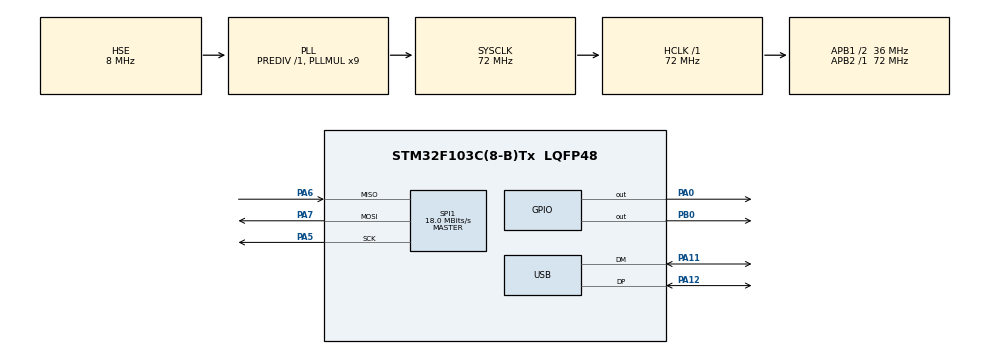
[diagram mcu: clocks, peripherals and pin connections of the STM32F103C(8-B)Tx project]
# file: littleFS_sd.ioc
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Mcu.Family=STM32F1
Mcu.Name=STM32F103C(8-B)Tx
Mcu.Package=LQFP48
NVIC.PriorityGroup=NVIC_PRIORITYGROUP_4
NVIC.TIM1_UP_IRQn=true\:0\:0\:false\:false\:true\:false\:true
NVIC.TimeBase=TIM1_UP_IRQn
NVIC.TimeBaseIP=TIM1
NVIC.USB_LP_CAN1_RX0_IRQn=true\:0\:0\:false\:false\:true\:false\:true
PA0-WKUP.Signal=GPIO_Output
PA11.Mode=Device
PA11.Signal=USB_DM
PA12.Mode=Device
PA12.Signal=USB_DP
PA13.Mode=Serial_Wire
PA13.Signal=SYS_JTMS-SWDIO
PA14.Mode=Serial_Wire
PA14.Signal=SYS_JTCK-SWCLK
PA5.Mode=Full_Duplex_Master
PA5.Signal=SPI1_SCK
PA6.Mode=Full_Duplex_Master
PA6.Signal=SPI1_MISO
PA7.Mode=Full_Duplex_Master
PA7.Signal=SPI1_MOSI
PB0.Signal=GPIO_Output
PC14-OSC32_IN.Mode=LSE-External-Oscillator
PC14-OSC32_IN.Signal=RCC_OSC32_IN
PC15-OSC32_OUT.Mode=LSE-External-Oscillator
PC15-OSC32_OUT.Signal=RCC_OSC32_OUT
PD0-OSC_IN.Mode=HSE-External-Oscillator
PD0-OSC_IN.Signal=RCC_OSC_IN
PD1-OSC_OUT.Mode=HSE-External-Oscillator
PD1-OSC_OUT.Signal=RCC_OSC_OUT
ProjectManager.HeapSize=0x200
ProjectManager.StackSize=0x400
ProjectManager.TargetToolchain=EWARM V8
RCC.AHBFreq_Value=72000000
RCC.APB1CLKDivider=RCC_HCLK_DIV2
RCC.APB1Freq_Value=36000000
RCC.APB1TimFreq_Value=72000000
RCC.APB2Freq_Value=72000000
RCC.APB2TimFreq_Value=72000000
RCC.HCLKFreq_Value=72000000
RCC.PLLMUL=RCC_PLL_MUL9
RCC.SYSCLKFreq_VALUE=72000000
RCC.SYSCLKSource=RCC_SYSCLKSOURCE_PLLCLK
RCC.USBFreq_Value=48000000
RCC.USBPrescaler=RCC_USBCLKSOURCE_PLL_DIV1_5
SPI1.BaudRatePrescaler=SPI_BAUDRATEPRESCALER_4
SPI1.CalculateBaudRate=18.0 MBits/s
SPI1.Direction=SPI_DIRECTION_2LINES
SPI1.Mode=SPI_MODE_MASTER
SPI1.VirtualType=VM_MASTER
USB_DEVICE.CLASS_NAME_FS=CDC
USB_DEVICE.VirtualMode=Cdc
USB_DEVICE.VirtualModeFS=Cdc_FS
VP_SYS_VS_tim1.Mode=TIM1
VP_USB_DEVICE_VS_USB_DEVICE_CDC_FS.Mode=CDC_FS
board=custom

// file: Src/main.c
/* USER CODE BEGIN Header */
/**
  ******************************************************************************
  * @file           : main.c
  * @brief          : Main program body
  ******************************************************************************
  * @attention
  *
  * <h2><center>&copy; Copyright (c) 2019 STMicroelectronics.
  * All rights reserved.</center></h2>
  *
  * This software component is licensed by ST under Ultimate Liberty license
  * SLA0044, the "License"; You may not use this file except in compliance with
  * the License. You may obtain a copy of the License at:
  *                             www.st.com/SLA0044
  *
  ******************************************************************************
  */
/* USER CODE END Header */

#include "main.h"
#include "usb_device.h"

/* USER CODE BEGIN Includes */
#include "user_diskio_spi/lfs.h"
#include "user_diskio_spi/fatfs_sd.h"
#include "user_diskio_spi/driver_sd.h"

/* USER CODE END Includes */

SPI_HandleTypeDef hspi1;

void SystemClock_Config(void);
static void MX_GPIO_Init(void);
static void MX_SPI1_Init(void);

/* USER CODE BEGIN 0 */

/*  // variables used by the filesystem
lfs_t lfs;
lfs_file_t file;

int block_device_read(const struct lfs_config *c, lfs_block_t block,  lfs_off_t off, void *buffer, lfs_size_t size) {
  uint8_t res;

  res = SD_disk_read(block*c->block_size + off, buffer, block, size);
  if (res != RES_ERROR) {
    return 1;
  }
  return 0;
}

int block_device_prog(const struct lfs_config *c, lfs_block_t block, lfs_off_t off, const void *buffer, lfs_size_t size) {
  uint8_t res;

  res = SD_disk_write(block*c->block_size + off, buffer, block, size);
  if (res != RES_ERROR) {
    return 1;
  }
  return 0;
}

// configuration of the filesystem is provided by this struct
const struct lfs_config cfg = {
  // block device operations
  .read  = block_device_read,
  .prog  = block_device_prog,
  .erase = 0,
  .sync  = 0,

    // block device configuration
    .read_size = 16,
    .prog_size = 16,
    .block_size = 4096,
    .block_count = 128,
    .cache_size = 16,
    .lookahead_size = 16,
    .block_cycles = 500,
};*/

/* USER CODE END 0 */

int main(void)
{

  /* MCU Configuration--------------------------------------------------------*/

  /* Reset of all peripherals, Initializes the Flash interface and the Systick. */
  HAL_Init();

  /* Configure the system clock */
  SystemClock_Config();

  /* Initialize all configured peripherals */
  MX_GPIO_Init();
  MX_SPI1_Init();
  MX_USB_DEVICE_Init();
  /* USER CODE BEGIN 2 */

/*  // mount the filesystem
    int err = lfs_mount(&lfs, &cfg);

    // reformat if we can't mount the filesystem
    // this should only happen on the first boot
    if (err) {
        lfs_format(&lfs, &cfg);
        lfs_mount(&lfs, &cfg);
    }

    // read current count
    uint32_t boot_count = 0;
    lfs_file_open(&lfs, &file, "boot_count", LFS_O_RDWR | LFS_O_CREAT);
    lfs_file_read(&lfs, &file, &boot_count, sizeof(boot_count));

    // update boot count
    boot_count += 1;
    lfs_file_rewind(&lfs, &file);
    lfs_file_write(&lfs, &file, &boot_count, sizeof(boot_count));

    // remember the storage is not updated until the file is closed successfully
    lfs_file_close(&lfs, &file);

    // release any resources we were using
    lfs_unmount(&lfs);

    // print the boot count
    printf("boot_count: %d\n", boot_count);
  */

  /* USER CODE END 2 */

  /* Infinite loop */
  /* USER CODE BEGIN WHILE */
  while (1)
  {

    sdDetecta();
    HAL_Delay(500);

    sdInicia();
    HAL_Delay(500);

    /* USER CODE END WHILE */

  }
}

void SystemClock_Config(void)
{
  RCC_OscInitTypeDef RCC_OscInitStruct = {0};
  RCC_ClkInitTypeDef RCC_ClkInitStruct = {0};
  RCC_PeriphCLKInitTypeDef PeriphClkInit = {0};

  /** Initializes the CPU, AHB and APB busses clocks
  */
  RCC_OscInitStruct.OscillatorType = RCC_OSCILLATORTYPE_HSE;
  RCC_OscInitStruct.HSEState = RCC_HSE_ON;
  RCC_OscInitStruct.HSEPredivValue = RCC_HSE_PREDIV_DIV1;
  RCC_OscInitStruct.HSIState = RCC_HSI_ON;
  RCC_OscInitStruct.PLL.PLLState = RCC_PLL_ON;
  RCC_OscInitStruct.PLL.PLLSource = RCC_PLLSOURCE_HSE;
  RCC_OscInitStruct.PLL.PLLMUL = RCC_PLL_MUL9;
  if (HAL_RCC_OscConfig(&RCC_OscInitStruct) != HAL_OK)
  {
    Error_Handler();
  }
  /** Initializes the CPU, AHB and APB busses clocks
  */
  RCC_ClkInitStruct.ClockType = RCC_CLOCKTYPE_HCLK|RCC_CLOCKTYPE_SYSCLK
                              |RCC_CLOCKTYPE_PCLK1|RCC_CLOCKTYPE_PCLK2;
  RCC_ClkInitStruct.SYSCLKSource = RCC_SYSCLKSOURCE_PLLCLK;
  RCC_ClkInitStruct.AHBCLKDivider = RCC_SYSCLK_DIV1;
  RCC_ClkInitStruct.APB1CLKDivider = RCC_HCLK_DIV2;
  RCC_ClkInitStruct.APB2CLKDivider = RCC_HCLK_DIV1;

  if (HAL_RCC_ClockConfig(&RCC_ClkInitStruct, FLASH_LATENCY_2) != HAL_OK)
  {
    Error_Handler();
  }
  PeriphClkInit.PeriphClockSelection = RCC_PERIPHCLK_USB;
  PeriphClkInit.UsbClockSelection = RCC_USBCLKSOURCE_PLL_DIV1_5;
  if (HAL_RCCEx_PeriphCLKConfig(&PeriphClkInit) != HAL_OK)
  {
    Error_Handler();
  }
}

static void MX_SPI1_Init(void)
{

  /* SPI1 parameter configuration*/
  hspi1.Instance = SPI1;
  hspi1.Init.Mode = SPI_MODE_MASTER;
  hspi1.Init.Direction = SPI_DIRECTION_2LINES;
  hspi1.Init.DataSize = SPI_DATASIZE_8BIT;
  hspi1.Init.CLKPolarity = SPI_POLARITY_LOW;
  hspi1.Init.CLKPhase = SPI_PHASE_1EDGE;
  hspi1.Init.NSS = SPI_NSS_SOFT;
  hspi1.Init.BaudRatePrescaler = SPI_BAUDRATEPRESCALER_4;
  hspi1.Init.FirstBit = SPI_FIRSTBIT_MSB;
  hspi1.Init.TIMode = SPI_TIMODE_DISABLE;
  hspi1.Init.CRCCalculation = SPI_CRCCALCULATION_DISABLE;
  hspi1.Init.CRCPolynomial = 10;
  if (HAL_SPI_Init(&hspi1) != HAL_OK)
  {
    Error_Handler();
  }

}

static void MX_GPIO_Init(void)
{
  GPIO_InitTypeDef GPIO_InitStruct = {0};

  /* GPIO Ports Clock Enable */
  __HAL_RCC_GPIOC_CLK_ENABLE();
  __HAL_RCC_GPIOD_CLK_ENABLE();
  __HAL_RCC_GPIOA_CLK_ENABLE();
  __HAL_RCC_GPIOB_CLK_ENABLE();

  /*Configure GPIO pin Output Level */
  HAL_GPIO_WritePin(GPIOA, GPIO_PIN_0, GPIO_PIN_RESET);

  /*Configure GPIO pin Output Level */
  HAL_GPIO_WritePin(GPIOB, GPIO_PIN_0, GPIO_PIN_RESET);

  /*Configure GPIO pin : PA0 */
  GPIO_InitStruct.Pin = GPIO_PIN_0;
  GPIO_InitStruct.Mode = GPIO_MODE_OUTPUT_PP;
  GPIO_InitStruct.Pull = GPIO_NOPULL;
  GPIO_InitStruct.Speed = GPIO_SPEED_FREQ_LOW;
  HAL_GPIO_Init(GPIOA, &GPIO_InitStruct);

  /*Configure GPIO pin : PB0 */
  GPIO_InitStruct.Pin = GPIO_PIN_0;
  GPIO_InitStruct.Mode = GPIO_MODE_OUTPUT_PP;
  GPIO_InitStruct.Pull = GPIO_NOPULL;
  GPIO_InitStruct.Speed = GPIO_SPEED_FREQ_LOW;
  HAL_GPIO_Init(GPIOB, &GPIO_InitStruct);

}

void HAL_TIM_PeriodElapsedCallback(TIM_HandleTypeDef *htim)
{
  if (htim->Instance == TIM1) {
    HAL_IncTick();
  }
}

void Error_Handler(void)
{
}

/************************ (C) COPYRIGHT STMicroelectronics *****END OF FILE****/
